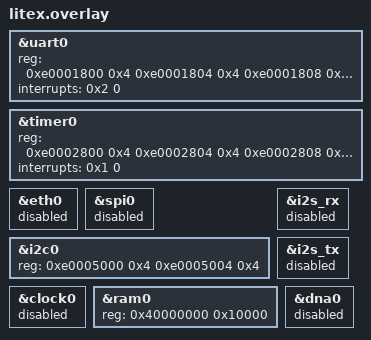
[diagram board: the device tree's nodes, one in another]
&uart0 {
	reg = <0xe0001800 0x4
		0xe0001804 0x4
		0xe0001808 0x4
		0xe000180c 0x4
		0xe0001810 0x4
		0xe0001814 0x4
		0xe0001818 0x4
		0xe000181c 0x4>;
	reg-names = "rxtx",
		"txfull",
		"rxempty",
		"ev_status",
		"ev_pending",
		"ev_enable",
		"txempty",
		"rxfull";
	interrupts = <0x2 0>;
};
&timer0 {
	reg = <0xe0002800 0x4
		0xe0002804 0x4
		0xe0002808 0x4
		0xe000280c 0x4
		0xe0002810 0x4
		0xe0002814 0x4
		0xe0002818 0x4
		0xe000281c 0x4
		0xe0002820 0x4
		0xe0002824 0x8>;
	reg-names = "load",
		"reload",
		"en",
		"update_value",
		"value",
		"ev_status",
		"ev_pending",
		"ev_enable",
		"uptime_latch",
		"uptime_cycles";
	interrupts = <0x1 0>;
};
&eth0 {
	status = "disabled";
};
&spi0 {
	status = "disabled";
};
&i2c0 {
	reg = <0xe0005000 0x4
		0xe0005004 0x4>;
	reg-names = "write",
		"read";
};
&i2s_rx {
	status = "disabled";
};
&i2s_tx {
	status = "disabled";
};
&clock0 {
	status = "disabled";
};
&ram0 {
	reg = <0x40000000 0x10000>;
};
&dna0 {
	status = "disabled";
};
